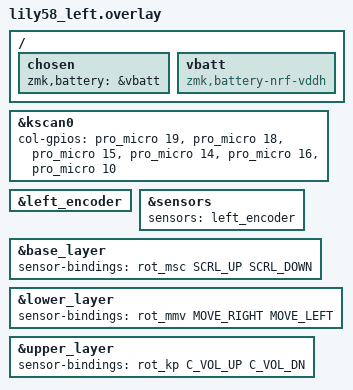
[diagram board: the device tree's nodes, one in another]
/*
 * Copyright (c) 2020 Pete Johanson
 *
 * SPDX-License-Identifier: MIT
 */

#include "lily58.dtsi"

&kscan0 {
    col-gpios
        = <&pro_micro 19 GPIO_ACTIVE_HIGH>
        , <&pro_micro 18 GPIO_ACTIVE_HIGH>
        , <&pro_micro 15 GPIO_ACTIVE_HIGH>
        , <&pro_micro 14 GPIO_ACTIVE_HIGH>
        , <&pro_micro 16 GPIO_ACTIVE_HIGH>
        , <&pro_micro 10 GPIO_ACTIVE_HIGH>
        ;
};

&left_encoder {
    status = "okay";
};

&sensors {
    sensors = <&left_encoder>;
};

/ {
    chosen {
      zmk,battery = &vbatt;
    };

    vbatt: vbatt {
        compatible = "zmk,battery-nrf-vddh";
    };
};
/* LEFT half: hat nur 1 Encoder-Sensor -> genau 1 Binding pro Layer */
&base_layer {
    /* links: vertical scroll */
    sensor-bindings = < &rot_msc SCRL_UP SCRL_DOWN >;
};

&lower_layer {
    /* links: Maus horizontal */
    sensor-bindings = < &rot_mmv MOVE_RIGHT MOVE_LEFT >;
};

&upper_layer {
    /* links: Lautstärke */
    sensor-bindings = < &rot_kp C_VOL_UP C_VOL_DN >;
};

